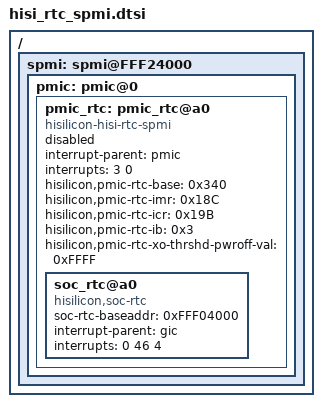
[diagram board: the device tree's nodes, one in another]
/*
 *  Copyright (C) 2012-2013 Linaro Ltd.
 *
 *  This program is free software; you can redistribute it and/or modify
 *  it under the terms of the GNU General Public License version 2 as
 *  publishhed by the Free Software Foundation.
 */

/ {
	spmi: spmi@FFF24000 {
		pmic: pmic@0 {
			pmic_rtc: pmic_rtc@a0 {
					compatible = "hisilicon-hisi-rtc-spmi";
					interrupt-parent = <&pmic>;
					interrupts = <3 0>;
					interrupt-names = "hisi-pmic-rtc";

					hisilicon,pmic-rtc-base = <0x340>;
					hisilicon,pmic-rtc-imr  = <0x18C>;
					hisilicon,pmic-rtc-icr  = <0x19B>;
					hisilicon,pmic-rtc-ib   = <0x3>;
					hisilicon,pmic-rtc-xo-thrshd-pwroff-val = <0xFFFF>;
					status = "disabled";
					soc_rtc@a0{
                        compatible = "hisilicon,soc-rtc";
                        soc-rtc-baseaddr = <0xFFF04000>;        /*SOC RTC BaseAddr*/
                        interrupt-parent = <&gic>;
                        interrupts = <0 46 4>;      /*SOC RTC IRQ*/
				};
			};
		};
	};
};
